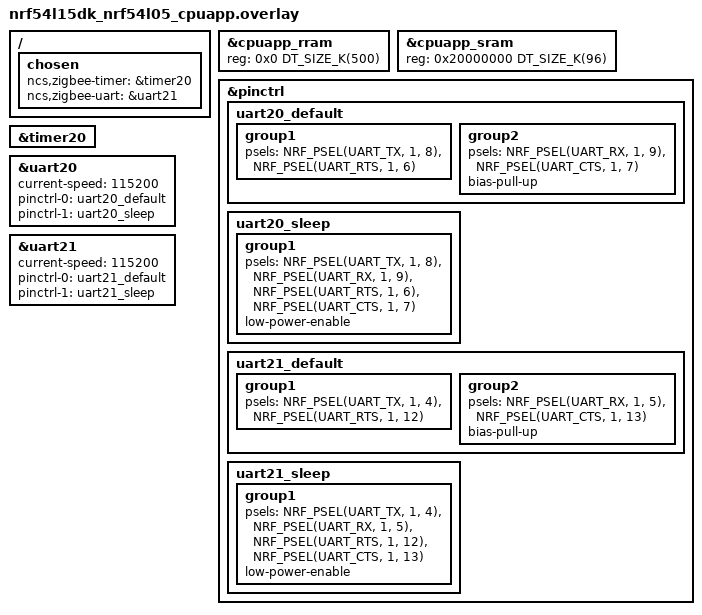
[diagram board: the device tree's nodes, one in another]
/*
 * Copyright (c) 2025 Nordic Semiconductor ASA
 *
 * SPDX-License-Identifier: LicenseRef-Nordic-5-Clause
 */


 / {
	chosen {
		ncs,zigbee-timer = &timer20;
        ncs,zigbee-uart = &uart21;
	};
};

// restore full RRAM and SRAM space - by default some parts are dedicated to FLPR
&cpuapp_rram {
	reg = <0x0 DT_SIZE_K(500)>;
};

&cpuapp_sram {
	reg = <0x20000000 DT_SIZE_K(96)>;
	ranges = <0x0 0x20000000  DT_SIZE_K(96)>;
};


&pinctrl {
	uart20_default: uart20_default {
		group1 {
			psels = <NRF_PSEL(UART_TX, 1, 8)>,
				<NRF_PSEL(UART_RTS, 1, 6)>;
		};
		group2 {
			psels = <NRF_PSEL(UART_RX, 1, 9)>,
				<NRF_PSEL(UART_CTS, 1, 7)>;
			bias-pull-up;
		};
	};

	uart20_sleep: uart20_sleep {
		group1 {
			psels = <NRF_PSEL(UART_TX, 1, 8)>,
				<NRF_PSEL(UART_RX, 1, 9)>,
				<NRF_PSEL(UART_RTS, 1, 6)>,
				<NRF_PSEL(UART_CTS, 1, 7)>;
			low-power-enable;
		};
	};

	uart21_default: uart21_default {
		group1 {
			psels = <NRF_PSEL(UART_TX, 1, 4)>,
				<NRF_PSEL(UART_RTS, 1, 12)>;
		};
		group2 {
			psels = <NRF_PSEL(UART_RX, 1, 5)>,
				<NRF_PSEL(UART_CTS, 1, 13)>;
			bias-pull-up;
		};
	};

	uart21_sleep: uart21_sleep {
		group1 {
			psels = <NRF_PSEL(UART_TX, 1, 4)>,
				<NRF_PSEL(UART_RX, 1, 5)>,
				<NRF_PSEL(UART_RTS, 1, 12)>,
				<NRF_PSEL(UART_CTS, 1, 13)>;
			low-power-enable;
		};
	};
};

&timer20 {
	status = "okay";
};

// TODO: re-enable HWFC once it's fixed
&uart20 {
	status = "okay";
	current-speed = <115200>;
	pinctrl-0 = <&uart20_default>;
	pinctrl-1 = <&uart20_sleep>;
	pinctrl-names = "default", "sleep";
	/delete-property/ hw-flow-control;
};

&uart21 {
	status = "okay";
	current-speed = <115200>;
	pinctrl-0 = <&uart21_default>;
	pinctrl-1 = <&uart21_sleep>;
	pinctrl-names = "default", "sleep";
	/delete-property/ hw-flow-control;
};
